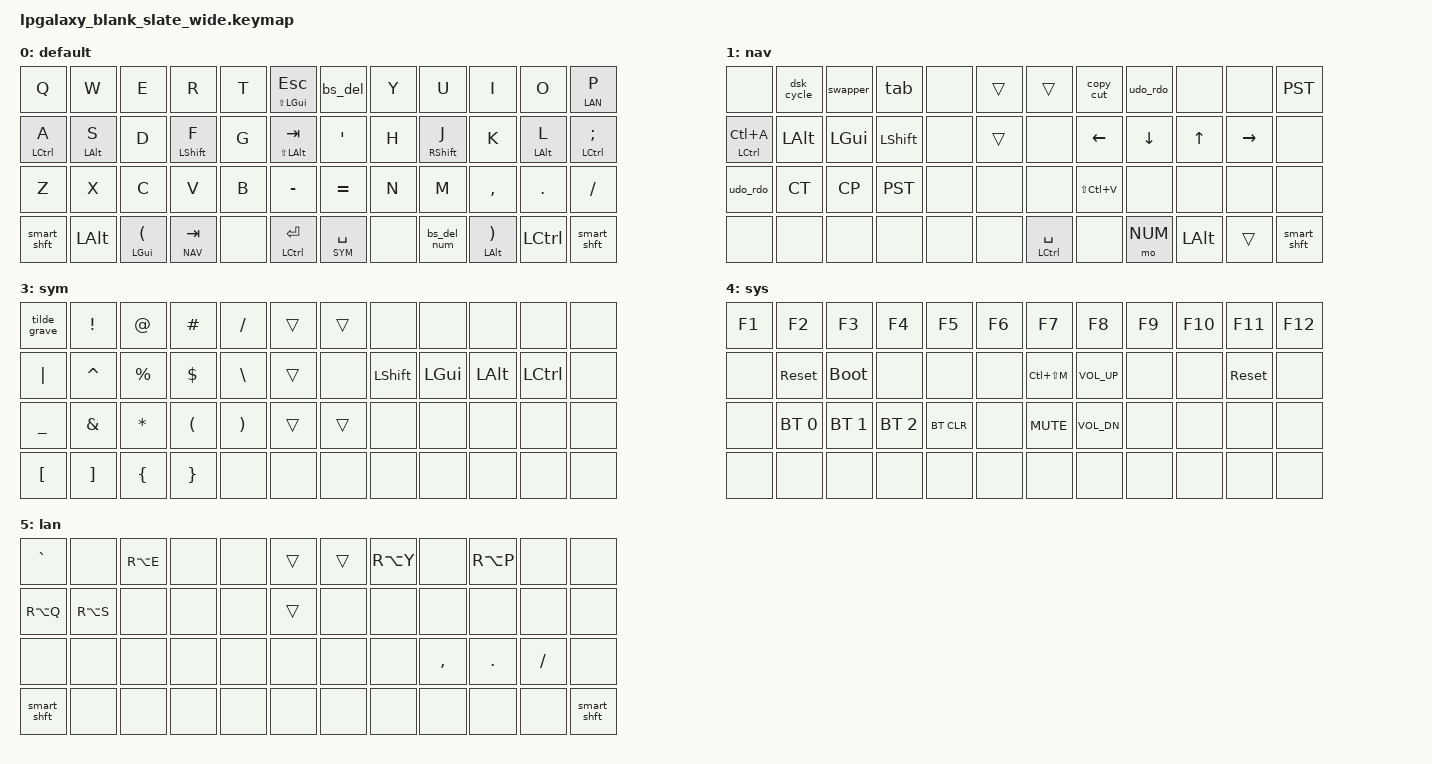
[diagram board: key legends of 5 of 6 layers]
/*
 * Copyright (c) 2020 The ZMK Contributors
 *
 * SPDX-License-Identifier: MIT
 */

#include "../zmk-nodefree-config/helper.h"
#include <behaviors.dtsi>
#include <dt-bindings/zmk/keys.h>
#include <dt-bindings/zmk/bt.h>
#define _BT_SEL_KEYS_ &bt BT_SEL 0 &bt BT_SEL 1 &bt BT_SEL 2 &bt BT_SEL 3 &bt BT_CLR

#include "../zmk-nodefree-config/keypos_def/keypos_48keys.h"
#include "../zmk-nodefree-config/international_chars/german.dtsi"

#define DEF 0
#define NAV 1
#define NUM 2
#define SYM 3
#define SYS 4
#define LAN 5

#define TAB_SWAP &tab
#define TAB_BK &tab_bk
#define APP_SWAP &swapper
#define APP_BK &swapper_bk

//OSX
// #define PREV_DSK &kp LC(LEFT)
// #define NEXT_DSK &kp LC(RIGHT)
// #define CP LG(C)
// #define CT LG(X)
// #define PST LG(V)
// #define UDO LG(Z)
// #define RDO LS(LG(Z))
// #define MOVE_MSG &kp LS(LG(M))

//WIN
#define PREV_DSK &kp LC(LG(LEFT))
#define NEXT_DSK &kp LC(LG(RIGHT))
#define CP LC(C)
#define CT LC(X)
#define PST LC(V)
#define UDO LC(Z)
#define RDO LS(LC(Z))
#define MOVE_MSG &kp LS(LC(V))


/*#include "combos.dtsi"  // requires layer aliases*/
/*#include "extra_keys.h"*/

/*layers and shortcuts*/
#define XXX &none
#define ___ &trans

/* Global settings */

#define QUICK_TAP_MS 175

&sk {  // sticky-key config
    release-after-ms = <900>;  // release after 0.6s
    quick-release;             // no double capitalization when rolling keys
};

&sl {  // sticky-layer config
    ignore-modifiers;          // allow chording sticky mods & layers
};

&lt {  // layer-tap config
    flavor = "balanced";
    tapping-term-ms = <200>;
    quick-tap-ms = <QUICK_TAP_MS>;
};

&mt {  // layer-tap config
    flavor = "balanced";
    tapping-term-ms = <200>;
    quick-tap-ms = <QUICK_TAP_MS>;
};
/*custom behaviors*/

// homerow mods
#define KEYS_L LT0 LT1 LT2 LT3 LT4 LT5 LM0 LM1 LM2 LM3 LM4 LM5 LB0 LB1 LB2 LB3 LB4 LB5  // left hand
#define KEYS_R RT0 RT1 RT2 RT3 RT4 RT5 RM0 RM1 RM2 RM3 RM4 RM5 RB0 RB1 RB2 RB3 RB4 RM5  // right hand
#define THUMBS LH4 LH3 LH2 LH1 LH0 RH0 RH1 RH2 RH3 RH4                                      // thumbs

/* left-hand HRMs */
ZMK_BEHAVIOR(hml, hold_tap,
    flavor = "balanced";
    tapping-term-ms = <250>;
    quick-tap-ms = <QUICK_TAP_MS>;                // repeat on tap-into-hold
    require-prior-idle-ms = <140>;
    bindings = <&kp>, <&kp>;
    hold-trigger-key-positions = <KEYS_R THUMBS>;
    hold-trigger-on-release;             // delay positional check until key-release
)
/* right-hand HRMs */
ZMK_BEHAVIOR(hmr, hold_tap,
    flavor = "balanced";
    tapping-term-ms = <250>;
    quick-tap-ms = <QUICK_TAP_MS>;                 // repeat on tap-into-hold
    require-prior-idle-ms = <140>;
    bindings = <&kp>, <&kp>;
    hold-trigger-key-positions = <KEYS_L THUMBS>;
    hold-trigger-on-release;             // delay positional check until key-release
)

ZMK_BEHAVIOR(hms, hold_tap,
    flavor = "balanced";
    tapping-term-ms = <250>;
    quick-tap-ms = <QUICK_TAP_MS>;                 // repeat on tap-into-hold
    require-prior-idle-ms = <140>;
    bindings = <&kp>, <&col_semi_inner>;
    hold-trigger-key-positions = <KEYS_L THUMBS>;
    hold-trigger-on-release;             // delay positional check until key-release
)

//normal: tilde, shift: grave
ZMK_BEHAVIOR(col_semi_inner, mod_morph,
    bindings = <&kp COLON>, <&kp SEMI>;
    mods = <(MOD_LSFT|MOD_RSFT)>;)

// tap: backspace | shift + tap: delete | hold: num layer
ZMK_BEHAVIOR(bs_del_num, mod_morph,
    bindings = <&lt NUM BSPC>, <&kp DEL>;
    mods = <(MOD_LSFT|MOD_RSFT)>;
)


// tap: backspace | shift + tap: delete 
ZMK_BEHAVIOR(bs_del, mod_morph,
    bindings = <&kp BSPC>, <&kp DEL>;
    mods = <(MOD_LSFT|MOD_RSFT)>;
)

/* Caps-word, num-word */
// tap: sticky-shift | shift + tap/ double-tap: caps-word | hold: shift
ZMK_BEHAVIOR(smart_shft, mod_morph,
    bindings = <&sk LSHFT>, <&caps_word>;
    mods = <(MOD_LSFT)>;
)
&caps_word {  // mods deactivate caps-word, requires PR #1451
    /delete-property/ ignore-modifiers;
    continue-list = <A B C D E F G H I J K L M N O P Q R S T U V W X Y Z UNDERSCORE MINUS>;
};                                                                                                                       // Alt+Tab swapper, requires PR #1366


ZMK_BEHAVIOR(swapper, tri_state,
    bindings = <&kt LALT>, <&kp TAB>, <&kt LALT>;
    ignored-key-positions = <LT2>;
)
ZMK_BEHAVIOR(swapper_bk, tri_state,
    bindings = <&kt LS(LALT)>, <&kp TAB>, <&kt LS(LALT)>;
    ignored-key-positions = <LT2>;
)

ZMK_BEHAVIOR(tab, tri_state,
    bindings = <&kt LCTRL>, <&kp TAB>, <&kt LCTRL>;
    ignored-key-positions = <LT2>;
)
ZMK_BEHAVIOR(tab_bk, tri_state,
    bindings = <&kt LS(LCTRL)>, <&kp TAB>, <&kt LS(LCTRL)>;
    ignored-key-positions = <LT2>;
)

//normal: tilde, shift: grave
ZMK_BEHAVIOR(tilde_grave, mod_morph,
    bindings = <&kp TILDE>, <&kp GRAVE>;
    mods = <(MOD_LSFT|MOD_RSFT)>;
)


ZMK_BEHAVIOR(dsk_cycle, tap_dance,
    tapping-term-ms = <200>;
    bindings = <NEXT_DSK>, <PREV_DSK>;
)

ZMK_BEHAVIOR(copy_cut, tap_dance,
    tapping-term-ms = <200>;
    bindings = <&kp CP>, <&kp CT>;
)

ZMK_BEHAVIOR(udo_rdo, tap_dance,
    tapping-term-ms = <200>;
    bindings = <&kp UDO>, <&kp RDO>;
)

#undef COMBO_TERM
#define COMBO_TERM 40  // timeout of 40ms (default is 30ms if omitted)
ZMK_COMBO(combo_copy,   &kp LG(C),  LB4 LB5, ALL)  // Ctrl + C, active on all layers
ZMK_COMBO(combo_paste,  &kp LG(V),  LB2 LB3, ALL)  // Ctrl + V, active on all layers
ZMK_COMBO(combo_tab,  &kp TAB,  LT4 LT5, ALL)  // esc
ZMK_COMBO(combo_esc,  &kp ESC,  RM2 RM3, ALL)  // esc
ZMK_COMBO(combo_bsp,  &kp BSPC,  RT4 RT5, ALL)  // backspace
ZMK_COMBO(combo_quotes,  &kp SQT,  RM4 RM5, DEF)  // quotes, only on default
ZMK_COMBO(combo_sym_minus,  &kp MINUS,  LT2 RT2, ALL)  // minus, all layers
ZMK_COMBO(combo_sym_under,  &kp UNDER,  LB2 RB2, ALL)  // under, all layers
ZMK_COMBO(combo_capsword,  &caps_word,  LH4 RH4, ALL)  // capsword, both shifts, all layers
ZMK_COMBO(combo_capsword,  &caps_word,  LM2 RM2, ALL)  // capsword, both hrm shifts, all layers

/* Keymap */

ZMK_CONDITIONAL_LAYER(NAV NUM, SYS)  // NAV + SYM --> SYS

ZMK_LAYER(default,
     // ╭─────────────┬─────────────┬─────────────┬─────────────┬─────────────┬────────────╮   ╭─────────────┬─────────────┬─────────────┬─────────────┬─────────────┬─────────────╮
             &kp Q          &kp W        &kp E         &kp R         &kp T    &mt LS(LGUI) ESC      &bs_del        &kp Y         &kp U         &kp I         &kp O         &lt LAN P
     // ├─────────────┼─────────────┼─────────────┬─────────────┼─────────────┼─────────────┤   ├─────────────┬─────────────┼─────────────┼─────────────┼─────────────┼─────────────┤
          &hml LCTRL A   &hml LALT S      &kp D     &hml LSHFT F     &kp G    &mt LS(LALT) TAB      &kp SQT        &kp H      &hmr RSHFT J     &kp K      &hmr LALT L &hmr LCTRL SEMI
     // ├─────────────┼─────────────┼─────────────┬─────────────┼─────────────┼─────────────┤   ├─────────────┬─────────────┼─────────────┼─────────────┼─────────────┼─────────────┤
          &kp Z         &kp X         &kp C         &kp V         &kp B          &kp MINUS         &kp EQUAL       &kp N        &kp M      &kp COMMA      &kp DOT        &kp FSLH
     // ╰─────────────┼─────────────┼─────────────┬─────────────┼─────────────┼─────────────┤   ├─────────────┬─────────────┼─────────────┼─────────────┼─────────────┼─────────────┤
          &smart_shft    &kp LALT   &mt LGUI LPAR  &lt NAV TAB       XXX    &mt LCTRL RET            &lt SYM SPACE   XXX        &bs_del_num  &mt LALT RPAR   &kp LCTRL     &smart_shft
     // ╰─────────────┴─────────────┴─────────────┴─────────────┴───────────────────────────╯   ╰───────────────────────────┴─────────────┴─────────────┴─────────────┴─────────────╯
)

ZMK_LAYER(nav,
     // ╭─────────────┬─────────────┬─────────────┬─────────────┬─────────────┬─────────────╮   ╭─────────────┬─────────────┬─────────────┬─────────────┬─────────────┬─────────────╮
             XXX       &dsk_cycle     APP_SWAP     TAB_SWAP          XXX            ___               ___        &copy_cut      &udo_rdo         XXX           XXX        &kp PST
     // ├─────────────┼─────────────┼─────────────┬─────────────┼─────────────┼─────────────┤   ├─────────────┬─────────────┼─────────────┼─────────────┼─────────────┼─────────────┤
        &mt LCTRL LC(A)  &kp LALT     &kp LGUI      &kp LSHFT        XXX            ___               XXX         &kp LEFT      &kp DOWN       &kp UP        &kp RIGHT       XXX
     // ├─────────────┼─────────────┼─────────────┬─────────────┼─────────────┼─────────────┤   ├─────────────┬─────────────┼─────────────┼─────────────┼─────────────┼─────────────┤
           &udo_rdo       &kp CT      &kp CP        &kp PST          XXX            XXX               XXX         MOVE_MSG       XXX            XXX           XXX           XXX
     // ╰─────────────┼─────────────┼─────────────┬─────────────┼─────────────┼─────────────┤   ├─────────────┬─────────────┼─────────────┼─────────────┼─────────────┼─────────────┤
             XXX             XXX          XXX            XXX           XXX        XXX              &mt LCTRL SPACE    XXX         &mo NUM      &kp LALT         ___          &smart_shft 
     // ╰─────────────┴─────────────┴─────────────┴─────────────┴───────────────────────────╯   ╰───────────────────────────┴─────────────┴─────────────┴─────────────┴─────────────╯
)

ZMK_LAYER(num,
     // ╭─────────────┬─────────────┬─────────────┬─────────────┬─────────────┬─────────────╮   ╭─────────────┬─────────────┬─────────────┬─────────────┬─────────────┬─────────────╮
            &kp MINUS      &kp N1        &kp N2         &kp N3       &kp PLUS        ___               ___          XXX           XXX          XXX            XXX          XXX
     // ├─────────────┼─────────────┼─────────────┬─────────────┼─────────────┼─────────────┤   ├─────────────┬─────────────┼─────────────┼─────────────┼─────────────┼─────────────┤
            &kp FSLH       &kp N4        &kp N5         &kp N6       &kp STAR        ___               XXX        &kp LSHFT     &kp LGUI      &kp LALT      &kp LCTRL
     // ├─────────────┼─────────────┼─────────────┬─────────────┼─────────────┼─────────────┤   ├─────────────┬─────────────┼─────────────┼─────────────┼─────────────┼─────────────┤
            &kp DOT        &kp N7        &kp N8         &kp N9       &kp EQUAL       ___               ___          XXX           XXX            XXX          XXX           XXX
     // ╰─────────────┼─────────────┼─────────────┬─────────────┼─────────────┼─────────────┤   ├─────────────┬─────────────┼─────────────┼─────────────┼─────────────┼─────────────┤
             XXX       &mt LGUI LPAR      &kp N0   &mt LCTRL RPAR      XXX       &kp LCTRL                  XXX      XXX          XXX                 XXX            XXX          XXX
     // ╰─────────────┴─────────────┴─────────────┴─────────────┴───────────────────────────╯   ╰───────────────────────────┴─────────────┴─────────────┴─────────────┴─────────────╯
)

ZMK_LAYER(sym,
     // ╭─────────────┬─────────────┬─────────────┬─────────────┬─────────────┬─────────────╮   ╭─────────────┬─────────────┬─────────────┬─────────────┬─────────────┬─────────────╮
         &tilde_grave     &kp EXCL      &kp AT       &kp HASH       &kp FSLH        ___               ___          XXX           XXX           XXX           XXX            XXX
     // ├─────────────┼─────────────┼─────────────┬─────────────┼─────────────┼─────────────┤   ├─────────────┬─────────────┼─────────────┼─────────────┼─────────────┼─────────────┤
           &kp PIPE      &kp CARET     &kp PRCNT      &kp DLLR      &kp BSLH        ___               XXX         &kp LSHFT     &kp LGUI       &kp LALT     &kp LCTRL       XXX
     // ├─────────────┼─────────────┼─────────────┬─────────────┼─────────────┼─────────────┤   ├─────────────┬─────────────┼─────────────┼─────────────┼─────────────┼─────────────┤
           &kp UNDER     &kp AMPS      &kp STAR       &kp LPAR      &kp RPAR        ___               ___           XXX           XXX          XXX           XXX           XXX
     // ╰─────────────┼─────────────┼─────────────┬─────────────┼─────────────┼─────────────┤   ├─────────────┬─────────────┼─────────────┼─────────────┼─────────────┼─────────────┤
            &kp LBKT     &kp RBKT      &kp LBRC      &kp RBRC               XXX          XXX     XXX        XXX                   XXX          XXX           XXX           XXX
     // ╰─────────────┴─────────────┴─────────────┴─────────────┴───────────────────────────╯   ╰───────────────────────────┴─────────────┴─────────────┴─────────────┴─────────────╯
)

ZMK_LAYER(sys,
     // ╭─────────────┬─────────────┬─────────────┬─────────────┬─────────────┬─────────────╮   ╭─────────────┬─────────────┬─────────────┬─────────────┬─────────────┬─────────────╮
            &kp F1         &kp F2        &kp F3       &kp F4        &kp F5       &kp F6              &kp F7        &kp F8       &kp F9       &kp F10        &kp F11       &kp F12
     // ├─────────────┼─────────────┼─────────────┬─────────────┼─────────────┼─────────────┤   ├─────────────┬─────────────┼─────────────┼─────────────┼─────────────┼─────────────┤
              XXX        &sys_reset    &bootloader      XXX           XXX          XXX           &kp LC(LS(M))  &kp C_VOL_UP      XXX           XXX        &sys_reset      XXX
     // ├─────────────┼─────────────┼─────────────┬─────────────┼─────────────┼─────────────┤   ├─────────────┬─────────────┼─────────────┼─────────────┼─────────────┼─────────────┤
              XXX       &bt BT_SEL 0  &bt BT_SEL 1  &bt BT_SEL 2   &bt BT_CLR      XXX            &kp C_MUTE    &kp C_VOL_DN      XXX           XXX           XXX          XXX
     // ╰─────────────┼─────────────┼─────────────┬─────────────┼─────────────┼─────────────┤   ├─────────────┬─────────────┼─────────────┼─────────────┼─────────────┼─────────────┤
              XXX            XXX         XXX            XXX                 XXX         XXX       XXX        XXX                  XXX           XXX          XXX             XXX
     // ╰─────────────┴─────────────┴─────────────┴─────────────┴───────────────────────────╯   ╰───────────────────────────┴─────────────┴─────────────┴─────────────┴─────────────╯
)

ZMK_LAYER(lan,
     // ╭─────────────┬─────────────┬─────────────┬─────────────┬─────────────┬────────────╮   ╭─────────────┬──────────────┬─────────────┬─────────────┬─────────────┬─────────────╮
           &kp GRAVE       XXX         &kp RA(E)       XXX           XXX            ___              ___         &kp RA(Y)       XXX         &kp RA(P)       XXX            XXX
     // ├─────────────┼─────────────┼─────────────┬─────────────┼─────────────┼─────────────┤   ├─────────────┬─────────────┼─────────────┼─────────────┼─────────────┼─────────────┤
          &kp RA(Q)      &kp RA(S)        XXX           XXX           XXX           ___              XXX           XXX           XXX           XXX           XXX            XXX
     // ├─────────────┼─────────────┼─────────────┬─────────────┼─────────────┼─────────────┤   ├─────────────┬─────────────┼─────────────┼─────────────┼─────────────┼─────────────┤
           XXX             XXX            XXX          XXX           XXX           XXX               XXX           XXX         &kp COMMA      &kp DOT       &kp FSLH        XXX 
     // ╰─────────────┼─────────────┼─────────────┬─────────────┼─────────────┼─────────────┤   ├─────────────┬─────────────┼─────────────┼─────────────┼─────────────┼─────────────┤
         &smart_shft            XXX         XXX            XXX                 XXX       XXX     XXX        XXX                  XXX           XXX          XXX         &smart_shft 
     // ╰─────────────┴─────────────┴─────────────┴─────────────┴───────────────────────────╯   ╰───────────────────────────┴─────────────┴─────────────┴─────────────┴─────────────╯
)
